AUTOSAR XML (schema 00046)
package /Application2_SWC_LedSwitching_package
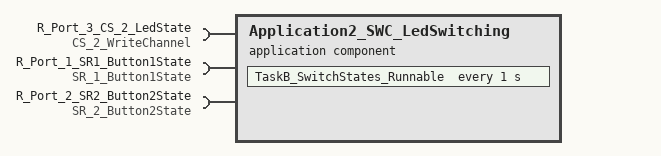
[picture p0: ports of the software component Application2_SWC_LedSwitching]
  application sw component type Application2_SWC_LedSwitching
    require port R_Port_3_CS_2_LedState: client-com-spec=CS_2_WriteChannel_Operation_1, required-interface=CS_2_WriteChannel
    require port R_Port_1_SR1_Button1State: nonqueued-receiver-com-spec{data-element=SR_1_Button1State_Element_1, init-value=SR_1_Button1State_Element_1:0}, required-interface=SR_1_Button1State
    require port R_Port_2_SR2_Button2State: nonqueued-receiver-com-spec{data-element=SR_2_Button2State_Element_1, init-value=SR_2_Button2State_Element_1:0}, required-interface=SR_2_Button2State
    behavior Application2_SWC_LedSwitching_internal_behavior
      timing event Periodic_Event_2_App2_SWC_event_event: start-on-event=TaskB_SwitchStates_Runnable, period=1
      runnable TaskB_SwitchStates_Runnable: symbol=TaskB_SwitchStates
        sync call TaskB_SwitchStates_Runnable_R_Port_3_CS_2_LedState_CS_2_WriteChannel_Operation_1: operation=R_Port_3_CS_2_LedState.CS_2_WriteChannel_Operation_1
